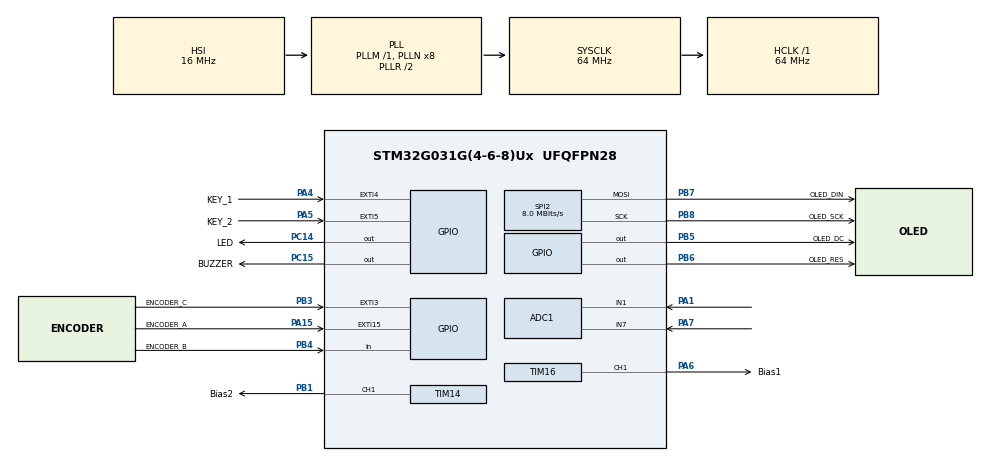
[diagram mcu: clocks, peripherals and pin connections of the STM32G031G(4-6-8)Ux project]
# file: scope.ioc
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ADC1.Channel-1\#ChannelRegularConversion=ADC_CHANNEL_1
ADC1.Channel-2\#ChannelRegularConversion=ADC_CHANNEL_7
ADC1.ClockPrescaler=ADC_CLOCK_SYNC_PCLK_DIV2
ADC1.DMAContinuousRequests=DISABLE
ADC1.EnableAnalogWatchDog1=false
ADC1.EnableAnalogWatchDog2=false
ADC1.ExternalTrigConv=ADC_EXTERNALTRIG_T3_TRGO
ADC1.NbrOfConversion=2
ADC1.NbrOfConversionFlag=1
ADC1.Overrun=ADC_OVR_DATA_PRESERVED
ADC1.OversamplingMode=DISABLE
ADC1.Rank-1\#ChannelRegularConversion=1
ADC1.Rank-2\#ChannelRegularConversion=2
ADC1.SamplingTime-1\#ChannelRegularConversion=ADC_SAMPLINGTIME_COMMON_1
ADC1.SamplingTime-2\#ChannelRegularConversion=ADC_SAMPLINGTIME_COMMON_1
ADC1.SamplingTimeCommon1=ADC_SAMPLETIME_1CYCLE_5
ADC1.SelectedChannel=ADC_CHANNEL_1|ADC_CHANNEL_7
ADC1.master=1
Dma.ADC1.0.Direction=DMA_PERIPH_TO_MEMORY
Dma.ADC1.0.EventEnable=DISABLE
Dma.ADC1.0.Instance=DMA1_Channel1
Dma.ADC1.0.MemDataAlignment=DMA_MDATAALIGN_HALFWORD
Dma.ADC1.0.MemInc=DMA_MINC_ENABLE
Dma.ADC1.0.Mode=DMA_NORMAL
Dma.ADC1.0.PeriphDataAlignment=DMA_PDATAALIGN_HALFWORD
Dma.ADC1.0.PeriphInc=DMA_PINC_DISABLE
Dma.ADC1.0.Polarity=HAL_DMAMUX_REQ_GEN_RISING
Dma.ADC1.0.Priority=DMA_PRIORITY_HIGH
Dma.ADC1.0.RequestNumber=1
Dma.ADC1.0.SignalID=NONE
Dma.ADC1.0.SyncEnable=DISABLE
Dma.ADC1.0.SyncPolarity=HAL_DMAMUX_SYNC_NO_EVENT
Dma.ADC1.0.SyncRequestNumber=1
Dma.ADC1.0.SyncSignalID=NONE
Dma.Request0=ADC1
Mcu.Family=STM32G0
Mcu.Name=STM32G031G(4-6-8)Ux
Mcu.Package=UFQFPN28
NVIC.ADC1_IRQn=true\:0\:0\:false\:false\:true\:true\:true
NVIC.DMA1_Channel1_IRQn=true\:0\:0\:false\:false\:true\:false\:true
NVIC.EXTI2_3_IRQn=true\:0\:0\:false\:false\:true\:true\:true
NVIC.EXTI4_15_IRQn=true\:0\:0\:false\:false\:true\:true\:true
NVIC.TIM17_IRQn=true\:0\:0\:false\:false\:true\:true\:true
NVIC.TIM1_BRK_UP_TRG_COM_IRQn=true\:0\:0\:false\:false\:true\:true\:true
PA1.Mode=IN1
PA1.Signal=ADC1_IN1
PA13.Mode=Serial_Wire
PA13.Signal=SYS_SWDIO
PA14-BOOT0.Mode=Serial_Wire
PA14-BOOT0.Signal=SYS_SWCLK
PA15.GPIO_Label=ENCODER_A
PA15.GPIO_ModeDefaultEXTI=GPIO_MODE_IT_RISING_FALLING
PA15.Signal=GPXTI15
PA4.GPIO_Label=KEY_1
PA4.GPIO_ModeDefaultEXTI=GPIO_MODE_IT_RISING_FALLING
PA4.Signal=GPXTI4
PA5.GPIO_Label=KEY_2
PA5.GPIO_ModeDefaultEXTI=GPIO_MODE_IT_RISING_FALLING
PA5.Signal=GPXTI5
PA6.GPIO_Label=Bias1
PA6.Signal=S_TIM16_CH1
PA7.Mode=IN7
PA7.Signal=ADC1_IN7
PB1.GPIO_Label=Bias2
PB1.Signal=S_TIM14_CH1
PB3.GPIO_Label=ENCODER_C
PB3.GPIO_ModeDefaultEXTI=GPIO_MODE_IT_RISING_FALLING
PB3.Signal=GPXTI3
PB4.GPIO_Label=ENCODER_B
PB4.Signal=GPIO_Input
PB5.GPIO_Label=OLED_DC
PB5.GPIO_Speed=GPIO_SPEED_FREQ_HIGH
PB5.Signal=GPIO_Output
PB6.GPIO_Label=OLED_RES
PB6.GPIO_Speed=GPIO_SPEED_FREQ_HIGH
PB6.Signal=GPIO_Output
PB7.GPIO_Label=OLED_DIN
PB7.Mode=TX_Only_Simplex_Unidirect_Master
PB7.Signal=SPI2_MOSI
PB8.GPIO_Label=OLED_SCK
PB8.Mode=TX_Only_Simplex_Unidirect_Master
PB8.Signal=SPI2_SCK
PC14-OSC32_IN\ (PC14).GPIO_Label=LED
PC14-OSC32_IN\ (PC14).Signal=GPIO_Output
PC15-OSC32_OUT\ (PC15).GPIO_Label=BUZZER
PC15-OSC32_OUT\ (PC15).PinState=GPIO_PIN_RESET
PC15-OSC32_OUT\ (PC15).Signal=GPIO_Output
ProjectManager.HeapSize=0x000
ProjectManager.StackSize=0x000
ProjectManager.TargetToolchain=STM32CubeIDE
RCC.ADCFreq_Value=64000000
RCC.AHBFreq_Value=64000000
RCC.CortexFreq_Value=64000000
RCC.EXTERNAL_CLOCK_VALUE=12288000
RCC.HCLKFreq_Value=64000000
RCC.HSE_VALUE=8000000
RCC.HSI_VALUE=16000000
RCC.LSE_VALUE=32768
RCC.SYSCLKFreq_VALUE=64000000
RCC.SYSCLKSource=RCC_SYSCLKSOURCE_PLLCLK
RCC.VCOOutputFreq_Value=128000000
SH.S_TIM14_CH1.0=TIM14_CH1,PWM Generation1 CH1
SH.S_TIM16_CH1.0=TIM16_CH1,PWM Generation1 CH1
SPI2.BaudRatePrescaler=SPI_BAUDRATEPRESCALER_8
SPI2.CLKPhase=SPI_PHASE_2EDGE
SPI2.CLKPolarity=SPI_POLARITY_HIGH
SPI2.CalculateBaudRate=8.0 MBits/s
SPI2.Direction=SPI_DIRECTION_2LINES
SPI2.Mode=SPI_MODE_MASTER
SPI2.VirtualType=VM_MASTER
TIM14.Channel=TIM_CHANNEL_1
TIM14.Period=98
TIM14.Pulse=33
TIM16.Channel=TIM_CHANNEL_1
TIM16.Period=98
TIM16.Pulse=33
TIM3.AutoReloadPreload=TIM_AUTORELOAD_PRELOAD_ENABLE
TIM3.Period=999
TIM3.TIM_MasterOutputTrigger=TIM_TRGO_UPDATE
VP_TIM14_VS_ClockSourceINT.Mode=Enable_Timer
VP_TIM16_VS_ClockSourceINT.Mode=Enable_Timer
VP_TIM17_VS_ClockSourceINT.Mode=Enable_Timer
VP_TIM1_VS_ClockSourceINT.Mode=Internal
VP_TIM3_VS_ClockSourceINT.Mode=Internal
board=custom

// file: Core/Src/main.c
/* USER CODE BEGIN Header */
/**
  ******************************************************************************
  * @file           : main.c
  * @brief          : Main program body
  ******************************************************************************
  * @attention
  *
  * Copyright (c) 2021 STMicroelectronics.
  * All rights reserved.
  *
  * This software is licensed under terms that can be found in the LICENSE file
  * in the root directory of this software component.
  * If no LICENSE file comes with this software, it is provided AS-IS.
  *
  ******************************************************************************
  */
/* USER CODE END Header */
#include "main.h"
#include "adc.h"
#include "dma.h"
#include "spi.h"
#include "tim.h"
#include "gpio.h"

/* USER CODE BEGIN Includes */
#include "../../OS/os.h"
/* USER CODE END Includes */

void SystemClock_Config(void);

int main(void)
{

  /* MCU Configuration--------------------------------------------------------*/

  /* Reset of all peripherals, Initializes the Flash interface and the Systick. */
  HAL_Init();

  /* Configure the system clock */
  SystemClock_Config();

  /* Initialize all configured peripherals */
  MX_GPIO_Init();
  MX_DMA_Init();
  MX_ADC1_Init();
  MX_TIM3_Init();
  MX_TIM16_Init();
  MX_SPI2_Init();
  MX_TIM14_Init();
  MX_TIM17_Init();
  MX_TIM1_Init();
  /* USER CODE BEGIN 2 */
    OS_Init();
  /* USER CODE END 2 */

  /* Infinite loop */
  /* USER CODE BEGIN WHILE */
  while (1) {
      OS_Loop();
    /* USER CODE END WHILE */

  }
}

void SystemClock_Config(void)
{
  RCC_OscInitTypeDef RCC_OscInitStruct = {0};
  RCC_ClkInitTypeDef RCC_ClkInitStruct = {0};

  /** Configure the main internal regulator output voltage
  */
  HAL_PWREx_ControlVoltageScaling(PWR_REGULATOR_VOLTAGE_SCALE1);
  /** Initializes the RCC Oscillators according to the specified parameters
  * in the RCC_OscInitTypeDef structure.
  */
  RCC_OscInitStruct.OscillatorType = RCC_OSCILLATORTYPE_HSI;
  RCC_OscInitStruct.HSIState = RCC_HSI_ON;
  RCC_OscInitStruct.HSIDiv = RCC_HSI_DIV1;
  RCC_OscInitStruct.HSICalibrationValue = RCC_HSICALIBRATION_DEFAULT;
  RCC_OscInitStruct.PLL.PLLState = RCC_PLL_ON;
  RCC_OscInitStruct.PLL.PLLSource = RCC_PLLSOURCE_HSI;
  RCC_OscInitStruct.PLL.PLLM = RCC_PLLM_DIV1;
  RCC_OscInitStruct.PLL.PLLN = 8;
  RCC_OscInitStruct.PLL.PLLP = RCC_PLLP_DIV2;
  RCC_OscInitStruct.PLL.PLLQ = RCC_PLLQ_DIV2;
  RCC_OscInitStruct.PLL.PLLR = RCC_PLLR_DIV2;
  if (HAL_RCC_OscConfig(&RCC_OscInitStruct) != HAL_OK)
  {
    Error_Handler();
  }
  /** Initializes the CPU, AHB and APB buses clocks
  */
  RCC_ClkInitStruct.ClockType = RCC_CLOCKTYPE_HCLK|RCC_CLOCKTYPE_SYSCLK
                              |RCC_CLOCKTYPE_PCLK1;
  RCC_ClkInitStruct.SYSCLKSource = RCC_SYSCLKSOURCE_PLLCLK;
  RCC_ClkInitStruct.AHBCLKDivider = RCC_SYSCLK_DIV1;
  RCC_ClkInitStruct.APB1CLKDivider = RCC_HCLK_DIV1;

  if (HAL_RCC_ClockConfig(&RCC_ClkInitStruct, FLASH_LATENCY_2) != HAL_OK)
  {
    Error_Handler();
  }
}

void Error_Handler(void)
{
  __disable_irq();
  while (1)
  {
  }
}
